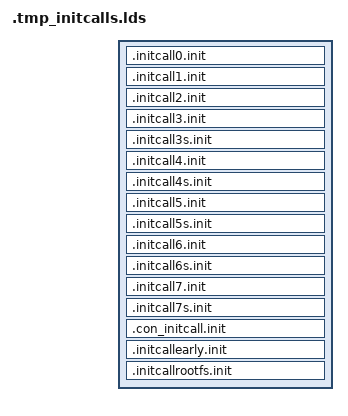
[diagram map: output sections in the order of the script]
SECTIONS {
	.initcall0.init : {
		*(.initcall0.init..kmod_core__515_845_bpf_jit_charge_init) ;
		*(.initcall0.init..kmod_min_addr__337_53_init_mmap_min_addr) ;
		*(.initcall0.init..kmod_pci__487_6842_pci_realloc_setup_params) ;
		*(.initcall0.init..kmod_inet_fragment__734_216_inet_frag_wq_init) ;
	}
	.initcall1.init : {
		*(.initcall1.init..kmod_fpsimd__355_1464_fpsimd_init) ;
		*(.initcall1.init..kmod_process__402_717_tagged_addr_init) ;
		*(.initcall1.init..kmod_topology__283_264_init_amu_fie) ;
		*(.initcall1.init..kmod_efi__363_173_arm64_efi_rt_init) ;
		*(.initcall1.init..kmod_armv8_deprecated__383_638_armv8_deprecated_init) ;
		*(.initcall1.init..kmod_kaslr__360_206_kaslr_init) ;
		*(.initcall1.init..kmod_cpu__492_1657_alloc_frozen_cpus) ;
		*(.initcall1.init..kmod_cpu__494_1704_cpu_hotplug_pm_sync_init) ;
		*(.initcall1.init..kmod_workqueue__573_5784_wq_sysfs_init) ;
		*(.initcall1.init..kmod_ksysfs__345_274_ksysfs_init) ;
		*(.initcall1.init..kmod_cpufreq_schedutil__558_853_schedutil_gov_init) ;
		*(.initcall1.init..kmod_main__462_962_pm_init) ;
		*(.initcall1.init..kmod_hibernate__470_1271_pm_disk_init) ;
		*(.initcall1.init..kmod_swap__466_1624_swsusp_header_init) ;
		*(.initcall1.init..kmod_update__452_350_rcu_set_runtime_mode) ;
		*(.initcall1.init..kmod_jiffies__324_69_init_jiffies_clocksource) ;
		*(.initcall1.init..kmod_core__442_4303_futex_init) ;
		*(.initcall1.init..kmod_cgroup__807_6030_cgroup_wq_init) ;
		*(.initcall1.init..kmod_cgroup_v1__385_1275_cgroup1_wq_init) ;
		*(.initcall1.init..kmod_trace_eprobe__407_1005_trace_events_eprobe_init_early) ;
		*(.initcall1.init..kmod_trace_events_synth__394_2307_trace_events_synth_init_early) ;
		*(.initcall1.init..kmod_trace_kprobe__419_1954_init_kprobe_trace_early) ;
		*(.initcall1.init..kmod_cpu_pm__293_213_cpu_pm_init) ;
		*(.initcall1.init..kmod_memcontrol__848_7607_mem_cgroup_swap_init) ;
		*(.initcall1.init..kmod_cma__403_177_cma_init_reserved_areas) ;
		*(.initcall1.init..kmod_fsnotify__368_572_fsnotify_init) ;
		*(.initcall1.init..kmod_locks__472_2983_filelock_init) ;
		*(.initcall1.init..kmod_binfmt_misc__399_834_init_misc_binfmt) ;
		*(.initcall1.init..kmod_binfmt_script__291_156_init_script_binfmt) ;
		*(.initcall1.init..kmod_binfmt_elf__404_2318_init_elf_binfmt) ;
		*(.initcall1.init..kmod_compat_binfmt_elf__404_2318_init_compat_elf_binfmt) ;
		*(.initcall1.init..kmod_configfs__379_178_configfs_init) ;
		*(.initcall1.init..kmod_debugfs__383_886_debugfs_init) ;
		*(.initcall1.init..kmod_tracefs__354_647_tracefs_init) ;
		*(.initcall1.init..kmod_inode__371_350_securityfs_init) ;
		*(.initcall1.init..kmod_gaf_v6__351_205_proca_init_gaf) ;
		*(.initcall1.init..kmod_random32__252_489_prandom_init_early) ;
		*(.initcall1.init..kmod_core__425_2329_pinctrl_init) ;
		*(.initcall1.init..kmod_gpiolib__449_4383_gpiolib_dev_init) ;
		*(.initcall1.init..kmod_crg_hi3516cv300__334_309_hi3516cv300_crg_init) ;
		*(.initcall1.init..kmod_clk_hi3519__334_194_hi3519_clk_init) ;
		*(.initcall1.init..kmod_clk_hi3559a__338_834_hi3559av100_crg_init) ;
		*(.initcall1.init..kmod_clk_hi3660__295_637_hi3660_clk_init) ;
		*(.initcall1.init..kmod_clk_hi3670__295_1016_hi3670_clk_init) ;
		*(.initcall1.init..kmod_crg_hi3798cv200__334_392_hi3798cv200_crg_init) ;
		*(.initcall1.init..kmod_clk_exynos5433__298_5728_exynos5433_cmu_init) ;
		*(.initcall1.init..kmod_virtio__361_534_virtio_init) ;
		*(.initcall1.init..kmod_core__562_6203_regulator_init) ;
		*(.initcall1.init..kmod_iommu__434_2807_iommu_init) ;
		*(.initcall1.init..kmod_component__300_123_component_debug_init) ;
		*(.initcall1.init..kmod_domain__518_2989_genpd_bus_init) ;
		*(.initcall1.init..kmod_soc__270_192_soc_bus_register) ;
		*(.initcall1.init..kmod_arch_topology__398_390_register_cpufreq_notifier) ;
		*(.initcall1.init..kmod_debugfs__302_256_opp_debug_init) ;
		*(.initcall1.init..kmod_cpufreq__535_2952_cpufreq_core_init) ;
		*(.initcall1.init..kmod_cpufreq_performance__319_44_cpufreq_gov_performance_init) ;
		*(.initcall1.init..kmod_cpufreq_powersave__319_38_cpufreq_gov_powersave_init) ;
		*(.initcall1.init..kmod_cpufreq_conservative__358_340_CPU_FREQ_GOV_CONSERVATIVE_init) ;
		*(.initcall1.init..kmod_cpuidle__477_792_cpuidle_init) ;
		*(.initcall1.init..kmod_arm_runtime__365_178_arm_dmi_init) ;
		*(.initcall1.init..kmod_hi3660_mailbox__339_291_hi3660_mbox_init) ;
		*(.initcall1.init..kmod_hi6220_mailbox__350_366_hi6220_mbox_init) ;
		*(.initcall1.init..kmod_socket__774_3158_sock_init) ;
		*(.initcall1.init..kmod_sock__884_3802_net_inuse_init) ;
		*(.initcall1.init..kmod_net_namespace__676_380_net_defaults_init) ;
		*(.initcall1.init..kmod_flow_dissector__791_1836_init_default_flow_dissectors) ;
		*(.initcall1.init..kmod_af_netlink__787_2914_netlink_proto_init) ;
		*(.initcall1.init..kmod_genetlink__670_1439_genl_init) ;
	}
	.initcall2.init : {
		*(.initcall2.init..kmod_debug_monitors__367_139_debug_monitors_init) ;
		*(.initcall2.init..kmod_irqdesc__310_335_irq_sysfs_init) ;
		*(.initcall2.init..kmod_pool__356_222_dma_atomic_pool_init) ;
		*(.initcall2.init..kmod_audit__692_1731_audit_init) ;
		*(.initcall2.init..kmod_tracepoint__307_140_release_early_probes) ;
		*(.initcall2.init..kmod_backing_dev__439_230_bdi_class_init) ;
		*(.initcall2.init..kmod_mm_init__389_206_mm_sysfs_init) ;
		*(.initcall2.init..kmod_page_alloc__663_8950_init_per_zone_wmark_min) ;
		*(.initcall2.init..kmod_ramoops__356_978_ramoops_init) ;
		*(.initcall2.init..kmod_mpi__345_64_mpi_init) ;
		*(.initcall2.init..kmod_kobject_uevent__661_814_kobject_uevent_init) ;
		*(.initcall2.init..kmod_probe__362_109_pcibus_class_init) ;
		*(.initcall2.init..kmod_pci_driver__508_1674_pci_driver_init) ;
		*(.initcall2.init..kmod_backlight__476_764_backlight_class_init) ;
		*(.initcall2.init..kmod_bus__471_331_amba_init) ;
		*(.initcall2.init..kmod_hi6220_reset__340_221_hi6220_reset_init) ;
		*(.initcall2.init..kmod_tty_io__408_3551_tty_class_init) ;
		*(.initcall2.init..kmod_serdev__323_859_serdev_init) ;
		*(.initcall2.init..kmod_iommu_sysfs__344_47_iommu_dev_init) ;
		*(.initcall2.init..kmod_drm_mipi_dsi__496_1343_mipi_dsi_bus_init) ;
		*(.initcall2.init..kmod_core__514_629_devlink_class_init) ;
		*(.initcall2.init..kmod_swnode__300_1176_software_node_init) ;
		*(.initcall2.init..kmod_wakeup__523_1266_wakeup_sources_debugfs_init) ;
		*(.initcall2.init..kmod_wakeup_stats__266_217_wakeup_sources_sysfs_init) ;
		*(.initcall2.init..kmod_regmap__442_3345_regmap_initcall) ;
		*(.initcall2.init..kmod_sram__303_474_sram_init) ;
		*(.initcall2.init..kmod_syscon__306_338_syscon_init) ;
		*(.initcall2.init..kmod_spi__585_4364_spi_init) ;
		*(.initcall2.init..kmod_spmi__402_600_spmi_init) ;
		*(.initcall2.init..kmod_i2c_core__522_1992_i2c_init) ;
		*(.initcall2.init..kmod_thermal_sys__534_1512_thermal_init) ;
		*(.initcall2.init..kmod_menu__286_579_init_menu) ;
		*(.initcall2.init..kmod_teo__284_534_teo_governor_init) ;
		*(.initcall2.init..kmod_rpmsg_core__339_749_rpmsg_init) ;
		*(.initcall2.init..kmod_rpmsg_char__413_555_rpmsg_chrdev_init) ;
	}
	.initcall3.init : {
		*(.initcall3.init..kmod_setup__373_287_reserve_memblock_reserved_regions) ;
		*(.initcall3.init..kmod_vdso__365_365_aarch32_alloc_vdso_pages) ;
		*(.initcall3.init..kmod_vdso__367_463_vdso_init) ;
		*(.initcall3.init..kmod_hw_breakpoint__379_1018_arch_hw_breakpoint_init) ;
		*(.initcall3.init..kmod_mmap__336_57_adjust_protection_map) ;
		*(.initcall3.init..kmod_context__369_394_asids_update_limit) ;
		*(.initcall3.init..kmod_kcmp__383_239_kcmp_cookies_init) ;
		*(.initcall3.init..kmod_cryptomgr__482_257_cryptomgr_init) ;
		*(.initcall3.init..kmod_clk_pll__287_76_samsung_pll_disable_early_timeout) ;
		*(.initcall3.init..kmod_dmaengine__363_293_dma_channel_table_init) ;
		*(.initcall3.init..kmod_dmaengine__424_1663_dma_bus_init) ;
		*(.initcall3.init..kmod_sunxi_mbus__345_127_sunxi_mbus_init) ;
		*(.initcall3.init..kmod_reset_hi3660__335_123_hi3660_reset_init) ;
		*(.initcall3.init..kmod_amba_pl011__497_3018_pl011_init) ;
		*(.initcall3.init..kmod_dma_iommu__392_1483_iommu_dma_init) ;
	}
	.initcall3s.init : {
		*(.initcall3s.init..kmod_platform__457_546_of_platform_default_populate_init) ;
	}
	.initcall4.init : {
		*(.initcall4.init..kmod_setup__375_415_topology_init) ;
		*(.initcall4.init..kmod_mte__453_601_register_mte_tcf_preferred_sysctl) ;
		*(.initcall4.init..kmod_user__308_263_uid_cache_init) ;
		*(.initcall4.init..kmod_params__392_974_param_sysfs_init) ;
		*(.initcall4.init..kmod_ucount__285_374_user_namespace_sysctl_init) ;
		*(.initcall4.init..kmod_stats__548_128_proc_schedstat_init) ;
		*(.initcall4.init..kmod_poweroff__187_45_pm_sysrq_init) ;
		*(.initcall4.init..kmod_profile__391_573_create_proc_profile) ;
		*(.initcall4.init..kmod_cgroup__815_6892_cgroup_sysfs_init) ;
		*(.initcall4.init..kmod_hung_task__460_322_hung_task_init) ;
		*(.initcall4.init..kmod_bpf_trace__720_2016_send_signal_irq_work_init) ;
		*(.initcall4.init..kmod_devmap__580_1145_dev_map_init) ;
		*(.initcall4.init..kmod_cpumap__556_824_cpu_map_init) ;
		*(.initcall4.init..kmod_net_namespace__523_566_netns_bpf_init) ;
		*(.initcall4.init..kmod_stackmap__512_738_stack_map_init) ;
		*(.initcall4.init..kmod_sysfs_btf__291_45_btf_vmlinux_init) ;
		*(.initcall4.init..kmod_oom_kill__493_728_oom_init) ;
		*(.initcall4.init..kmod_backing_dev__441_240_default_bdi_init) ;
		*(.initcall4.init..kmod_backing_dev__477_765_cgwb_init) ;
		*(.initcall4.init..kmod_percpu__518_3379_percpu_enable_async) ;
		*(.initcall4.init..kmod_compaction__559_3137_kcompactd_init) ;
		*(.initcall4.init..kmod_mmap__542_3764_init_user_reserve) ;
		*(.initcall4.init..kmod_mmap__546_3785_init_admin_reserve) ;
		*(.initcall4.init..kmod_mmap__548_3855_init_reserve_notifier) ;
		*(.initcall4.init..kmod_swap_state__473_911_swap_init_sysfs) ;
		*(.initcall4.init..kmod_swapfile__549_3858_swapfile_init) ;
		*(.initcall4.init..kmod_huge_memory__485_461_hugepage_init) ;
		*(.initcall4.init..kmod_memcontrol__839_7251_mem_cgroup_init) ;
		*(.initcall4.init..kmod_seqiv__384_183_seqiv_module_init) ;
		*(.initcall4.init..kmod_echainiv__384_160_echainiv_module_init) ;
		*(.initcall4.init..kmod_rsa_generic__352_281_rsa_init) ;
		*(.initcall4.init..kmod_cmac__303_311_crypto_cmac_module_init) ;
		*(.initcall4.init..kmod_hmac__380_254_hmac_module_init) ;
		*(.initcall4.init..kmod_xcbc__303_270_crypto_xcbc_module_init) ;
		*(.initcall4.init..kmod_crypto_null__369_221_crypto_null_mod_init) ;
		*(.initcall4.init..kmod_md5__303_245_md5_mod_init) ;
		*(.initcall4.init..kmod_sha1_generic__357_89_sha1_generic_mod_init) ;
		*(.initcall4.init..kmod_sha256_generic__355_113_sha256_generic_mod_init) ;
		*(.initcall4.init..kmod_sha512_generic__355_218_sha512_generic_mod_init) ;
		*(.initcall4.init..kmod_blake2b_generic__303_174_blake2b_mod_init) ;
		*(.initcall4.init..kmod_ecb__301_99_crypto_ecb_module_init) ;
		*(.initcall4.init..kmod_cbc__301_218_crypto_cbc_module_init) ;
		*(.initcall4.init..kmod_cts__378_405_crypto_cts_module_init) ;
		*(.initcall4.init..kmod_xts__378_469_xts_module_init) ;
		*(.initcall4.init..kmod_ctr__303_355_crypto_ctr_module_init) ;
		*(.initcall4.init..kmod_adiantum__395_613_adiantum_module_init) ;
		*(.initcall4.init..kmod_nhpoly1305__312_248_nhpoly1305_mod_init) ;
		*(.initcall4.init..kmod_gcm__396_1159_crypto_gcm_module_init) ;
		*(.initcall4.init..kmod_ccm__398_949_crypto_ccm_module_init) ;
		*(.initcall4.init..kmod_chacha20poly1305__396_671_chacha20poly1305_module_init) ;
		*(.initcall4.init..kmod_des_generic__299_125_des_generic_mod_init) ;
		*(.initcall4.init..kmod_twofish_generic__293_190_twofish_mod_init) ;
		*(.initcall4.init..kmod_aes_generic__293_1314_aes_init) ;
		*(.initcall4.init..kmod_chacha_generic__301_128_chacha_generic_mod_init) ;
		*(.initcall4.init..kmod_poly1305_generic__305_142_poly1305_mod_init) ;
		*(.initcall4.init..kmod_deflate__353_334_deflate_mod_init) ;
		*(.initcall4.init..kmod_crc32c_generic__303_161_crc32c_mod_init) ;
		*(.initcall4.init..kmod_crc32_generic__303_125_crc32_mod_init) ;
		*(.initcall4.init..kmod_authenc__500_464_crypto_authenc_module_init) ;
		*(.initcall4.init..kmod_authencesn__499_479_crypto_authenc_esn_module_init) ;
		*(.initcall4.init..kmod_lzo__347_158_lzo_mod_init) ;
		*(.initcall4.init..kmod_lzo_rle__347_158_lzorle_mod_init) ;
		*(.initcall4.init..kmod_lz4__324_155_lz4_mod_init) ;
		*(.initcall4.init..kmod_ansi_cprng__302_470_prng_mod_init) ;
		*(.initcall4.init..kmod_drbg__374_2144_drbg_init) ;
		*(.initcall4.init..kmod_ghash_generic__306_178_ghash_mod_init) ;
		*(.initcall4.init..kmod_zstd__353_253_zstd_mod_init) ;
		*(.initcall4.init..kmod_essiv__395_646_essiv_module_init) ;
		*(.initcall4.init..kmod_ecdh_generic__351_238_ecdh_init) ;
		*(.initcall4.init..kmod_bio__490_1747_init_bio) ;
		*(.initcall4.init..kmod_blk_ioc__423_423_blk_ioc_init) ;
		*(.initcall4.init..kmod_blk_mq__540_4089_blk_mq_init) ;
		*(.initcall4.init..kmod_genhd__444_887_genhd_device_init) ;
		*(.initcall4.init..kmod_blk_cgroup__517_1956_blkcg_init) ;
		*(.initcall4.init..kmod_blk_crypto__408_80_bio_crypt_ctx_init) ;
		*(.initcall4.init..kmod_io_wq__498_1414_io_wq_init) ;
		*(.initcall4.init..kmod_gpiolib__454_4510_gpiolib_debugfs_init) ;
		*(.initcall4.init..kmod_core__408_1244_pwm_debugfs_init) ;
		*(.initcall4.init..kmod_sysfs__266_546_pwm_sysfs_init) ;
		*(.initcall4.init..kmod_slot__370_380_pci_slot_init) ;
		*(.initcall4.init..kmod_clk_hi6220_stub__300_272_hi6220_stub_clk_init) ;
		*(.initcall4.init..kmod_clk_hi3660_stub__336_178_hi3660_stub_clk_init) ;
		*(.initcall4.init..kmod_fixed__452_348_regulator_fixed_voltage_init) ;
		*(.initcall4.init..kmod_misc__321_291_misc_init) ;
		*(.initcall4.init..kmod_iommu__358_155_iommu_subsys_init) ;
		*(.initcall4.init..kmod_arch_topology__393_209_register_cpu_capacity_sysctl) ;
		*(.initcall4.init..kmod_act8945a__454_82_act8945a_i2c_init) ;
		*(.initcall4.init..kmod_libnvdimm__463_606_libnvdimm_init) ;
		*(.initcall4.init..kmod_dax__417_719_dax_core_init) ;
		*(.initcall4.init..kmod_dma_buf__389_1604_dma_buf_init) ;
		*(.initcall4.init..kmod_dma_heap__403_483_dma_heap_init) ;
		*(.initcall4.init..kmod_scsi_mod__470_821_init_scsi) ;
		*(.initcall4.init..kmod_libphy__536_3260_phy_init) ;
		*(.initcall4.init..kmod_usb_common__469_432_usb_common_init) ;
		*(.initcall4.init..kmod_usbcore__491_1195_usb_init) ;
		*(.initcall4.init..kmod_udc_core__422_1789_usb_udc_init) ;
		*(.initcall4.init..kmod_typec__393_2181_typec_init) ;
		*(.initcall4.init..kmod_roles__320_399_usb_roles_init) ;
		*(.initcall4.init..kmod_serio__395_1051_serio_init) ;
		*(.initcall4.init..kmod_input_core__432_2653_input_init) ;
		*(.initcall4.init..kmod_rtc_core__344_478_rtc_init) ;
		*(.initcall4.init..kmod_i3c__512_2704_i3c_init) ;
		*(.initcall4.init..kmod_mc__352_323_media_devnode_init) ;
		*(.initcall4.init..kmod_videodev__500_1132_videodev_init) ;
		*(.initcall4.init..kmod_rc_core__373_2090_rc_core_init) ;
		*(.initcall4.init..kmod_cec__363_451_cec_devnode_init) ;
		*(.initcall4.init..kmod_pps_core__307_484_pps_init) ;
		*(.initcall4.init..kmod_ptp__439_465_ptp_init) ;
		*(.initcall4.init..kmod_power_supply__329_1398_power_supply_class_init) ;
		*(.initcall4.init..kmod_edac_core__357_163_edac_init) ;
		*(.initcall4.init..kmod_cpuidle_psci_domain__272_317_psci_idle_init_domains) ;
		*(.initcall4.init..kmod_mmc_core__493_2373_mmc_init) ;
		*(.initcall4.init..kmod_led_class__309_549_leds_init) ;
		*(.initcall4.init..kmod_scmi_module__520_2108_scmi_driver_init) ;
		*(.initcall4.init..kmod_efi__355_439_efisubsys_init) ;
		*(.initcall4.init..kmod_remoteproc__428_2864_remoteproc_init) ;
		*(.initcall4.init..kmod_devfreq__446_2024_devfreq_init) ;
		*(.initcall4.init..kmod_devfreq_event__277_482_devfreq_event_init) ;
		*(.initcall4.init..kmod_governor_simpleondemand__302_130_devfreq_simple_ondemand_init) ;
		*(.initcall4.init..kmod_governor_performance__302_48_devfreq_performance_init) ;
		*(.initcall4.init..kmod_governor_powersave__302_48_devfreq_powersave_init) ;
		*(.initcall4.init..kmod_governor_userspace__306_143_devfreq_userspace_init) ;
		*(.initcall4.init..kmod_governor_passive__303_177_devfreq_passive_init) ;
		*(.initcall4.init..kmod_industrialio__359_2139_iio_init) ;
		*(.initcall4.init..kmod_arm_pmu__391_975_arm_pmu_hp_init) ;
		*(.initcall4.init..kmod_ras__396_38_ras_init) ;
		*(.initcall4.init..kmod_nvmem_core__343_1922_nvmem_init) ;
		*(.initcall4.init..kmod_soundcore__308_65_init_soundcore) ;
		*(.initcall4.init..kmod_snd__320_426_alsa_sound_init) ;
		*(.initcall4.init..kmod_sock__890_4114_proto_init) ;
		*(.initcall4.init..kmod_dev__1210_11737_net_dev_init) ;
		*(.initcall4.init..kmod_neighbour__786_3766_neigh_init) ;
		*(.initcall4.init..kmod_fib_notifier__484_199_fib_notifier_init) ;
		*(.initcall4.init..kmod_fib_rules__783_1298_fib_rules_init) ;
		*(.initcall4.init..kmod_netprio_cgroup__680_295_init_cgroup_netprio) ;
		*(.initcall4.init..kmod_devlink__855_11573_devlink_init) ;
		*(.initcall4.init..kmod_sch_api__698_2354_pktsched_init) ;
		*(.initcall4.init..kmod_cls_api__840_3924_tc_filter_init) ;
		*(.initcall4.init..kmod_act_api__681_1719_tc_action_init) ;
		*(.initcall4.init..kmod_ethtool_nl__660_1036_ethnl_init) ;
		*(.initcall4.init..kmod_nexthop__822_3772_nexthop_init) ;
		*(.initcall4.init..kmod_bluetooth__683_804_bt_init) ;
		*(.initcall4.init..kmod_wext_core__484_408_wireless_nlevent_init) ;
		*(.initcall4.init..kmod_rfkill__366_1418_rfkill_init) ;
		*(.initcall4.init..kmod_ieee802154__483_374_wpan_phy_class_init) ;
		*(.initcall4.init..kmod_mac802154__694_235_ieee802154_init) ;
		*(.initcall4.init..kmod_nfc__670_1239_nfc_init) ;
	}
	.initcall4s.init : {
		*(.initcall4s.init..kmod_cpufeature__397_2979_init_32bit_el0_mask) ;
		*(.initcall4s.init..kmod_watchdog__462_475_watchdog_init) ;
	}
	.initcall5.init : {
		*(.initcall5.init..kmod_debug_monitors__365_63_create_debug_debugfs_entry) ;
		*(.initcall5.init..kmod_resource__366_1876_iomem_init_inode) ;
		*(.initcall5.init..kmod_energy_model__301_99_em_debug_init) ;
		*(.initcall5.init..kmod_clocksource__347_1074_clocksource_done_booting) ;
		*(.initcall5.init..kmod_trace__487_9856_tracer_init_tracefs) ;
		*(.initcall5.init..kmod_trace_printk__386_415_init_trace_printk_function_export) ;
		*(.initcall5.init..kmod_trace_events_synth__396_2331_trace_events_synth_init) ;
		*(.initcall5.init..kmod_bpf_trace__725_2069_bpf_event_init) ;
		*(.initcall5.init..kmod_trace_kprobe__421_1984_init_kprobe_trace) ;
		*(.initcall5.init..kmod_trace_dynevent__391_276_init_dynamic_event) ;
		*(.initcall5.init..kmod_trace_uprobe__429_1674_init_uprobe_trace) ;
		*(.initcall5.init..kmod_inode__539_839_bpf_init) ;
		*(.initcall5.init..kmod_btf__780_6178_btf_module_init) ;
		*(.initcall5.init..kmod_pipe__470_1450_init_pipe_fs) ;
		*(.initcall5.init..kmod_fs_writeback__541_1175_cgroup_writeback_init) ;
		*(.initcall5.init..kmod_inotify_user__486_875_inotify_user_setup) ;
		*(.initcall5.init..kmod_eventpoll__765_2452_eventpoll_init) ;
		*(.initcall5.init..kmod_anon_inodes__347_241_anon_inode_init) ;
		*(.initcall5.init..kmod_locks__470_2960_proc_locks_init) ;
		*(.initcall5.init..kmod_iomap__478_1539_iomap_init) ;
		*(.initcall5.init..kmod_dquot__487_3072_dquot_init) ;
		*(.initcall5.init..kmod_proc__283_19_proc_cmdline_init) ;
		*(.initcall5.init..kmod_proc__308_98_proc_consoles_init) ;
		*(.initcall5.init..kmod_proc__311_32_proc_cpuinfo_init) ;
		*(.initcall5.init..kmod_proc__405_60_proc_devices_init) ;
		*(.initcall5.init..kmod_proc__323_42_proc_interrupts_init) ;
		*(.initcall5.init..kmod_proc__338_33_proc_loadavg_init) ;
		*(.initcall5.init..kmod_proc__451_186_proc_meminfo_init) ;
		*(.initcall5.init..kmod_proc__326_242_proc_stat_init) ;
		*(.initcall5.init..kmod_proc__323_45_proc_uptime_init) ;
		*(.initcall5.init..kmod_proc__283_23_proc_version_init) ;
		*(.initcall5.init..kmod_proc__323_33_proc_softirqs_init) ;
		*(.initcall5.init..kmod_proc__315_66_proc_kmsg_init) ;
		*(.initcall5.init..kmod_proc__462_338_proc_page_init) ;
		*(.initcall5.init..kmod_proc__285_96_proc_boot_config_init) ;
		*(.initcall5.init..kmod_ramfs__427_295_init_ramfs_fs) ;
		*(.initcall5.init..kmod_dynamic_debug__718_1143_dynamic_debug_init_control) ;
		*(.initcall5.init..kmod_mem__471_777_chr_dev_init) ;
		*(.initcall5.init..kmod_firmware_class__468_1655_firmware_class_init) ;
		*(.initcall5.init..kmod_powercap_sys__333_677_powercap_init) ;
		*(.initcall5.init..kmod_sysctl_net_core__723_666_sysctl_core_init) ;
		*(.initcall5.init..kmod_eth__734_499_eth_offload_init) ;
		*(.initcall5.init..kmod_af_inet__829_1933_ipv4_offload_init) ;
		*(.initcall5.init..kmod_af_inet__832_2064_inet_init) ;
		*(.initcall5.init..kmod_unix__722_3465_af_unix_init) ;
		*(.initcall5.init..kmod_ip6_offload__757_448_ipv6_offload_init) ;
		*(.initcall5.init..kmod_vlan_core__508_566_vlan_offload_init) ;
		*(.initcall5.init..kmod_xsk__787_1520_xsk_init) ;
	}
	.initcall5s.init : {
		*(.initcall5s.init..kmod_quirks__460_194_pci_apply_final_quirks) ;
	}
	.initcall6.init : {
		*(.initcall6.init..kmod_setup__377_449_register_arm64_panic_block) ;
		*(.initcall6.init..kmod_cpuinfo__302_328_cpuinfo_regs_init) ;
		*(.initcall6.init..kmod_cpufeature__394_1370_aarch32_el0_sysfs_init) ;
		*(.initcall6.init..kmod_perf_event__415_1319_armv8_pmu_driver_init) ;
		*(.initcall6.init..kmod_uprobes__370_208_arch_init_uprobes) ;
		*(.initcall6.init..kmod_kvm__609_2373_arm_init) ;
		*(.initcall6.init..kmod_sha1_ce__310_146_cpu_feature_match_SHA1_init) ;
		*(.initcall6.init..kmod_sha2_ce__312_182_cpu_feature_match_SHA2_init) ;
		*(.initcall6.init..kmod_sha512_ce__311_120_cpu_feature_match_SHA512_init) ;
		*(.initcall6.init..kmod_ghash_ce__404_623_ghash_ce_mod_init) ;
		*(.initcall6.init..kmod_aes_ce_cipher__298_178_cpu_feature_match_AES_init) ;
		*(.initcall6.init..kmod_aes_glue_ce__414_1050_cpu_feature_match_AES_init) ;
		*(.initcall6.init..kmod_sha256_arm64__312_194_sha256_mod_init) ;
		*(.initcall6.init..kmod_sha512_arm64__312_91_sha512_mod_init) ;
		*(.initcall6.init..kmod_chacha_neon__305_232_chacha_simd_mod_init) ;
		*(.initcall6.init..kmod_poly1305_neon__309_226_neon_poly1305_mod_init) ;
		*(.initcall6.init..kmod_exec_domain__377_35_proc_execdomains_init) ;
		*(.initcall6.init..kmod_panic__383_754_register_warn_debugfs) ;
		*(.initcall6.init..kmod_cpu__501_2647_cpuhp_sysfs_init) ;
		*(.initcall6.init..kmod_resource__348_137_ioresources_init) ;
		*(.initcall6.init..kmod_psi__578_1462_psi_proc_init) ;
		*(.initcall6.init..kmod_user__455_462_snapshot_device_init) ;
		*(.initcall6.init..kmod_generic_chip__314_665_irq_gc_init_ops) ;
		*(.initcall6.init..kmod_pm__451_249_irq_pm_init_ops) ;
		*(.initcall6.init..kmod_timekeeping__370_1905_timekeeping_init_ops) ;
		*(.initcall6.init..kmod_clocksource__360_1475_init_clocksource_sysfs) ;
		*(.initcall6.init..kmod_timer_list__345_359_init_timer_list_procfs) ;
		*(.initcall6.init..kmod_alarmtimer__406_964_alarmtimer_init) ;
		*(.initcall6.init..kmod_posix_timers__381_280_init_posix_timers) ;
		*(.initcall6.init..kmod_clockevents__354_776_clockevents_init_sysfs) ;
		*(.initcall6.init..kmod_sched_clock__297_300_sched_clock_syscore_init) ;
		*(.initcall6.init..kmod_module__460_4821_proc_modules_init) ;
		*(.initcall6.init..kmod_kallsyms__505_864_kallsyms_init) ;
		*(.initcall6.init..kmod_configs__291_75_ikconfig_init) ;
		*(.initcall6.init..kmod_kheaders__291_61_ikheaders_init) ;
		*(.initcall6.init..kmod_audit_watch__436_503_audit_watch_init) ;
		*(.initcall6.init..kmod_audit_fsnotify__420_193_audit_fsnotify_init) ;
		*(.initcall6.init..kmod_audit_tree__449_1085_audit_tree_init) ;
		*(.initcall6.init..kmod_seccomp__592_2369_seccomp_sysctl_init) ;
		*(.initcall6.init..kmod_utsname_sysctl__236_144_utsname_sysctl_init) ;
		*(.initcall6.init..kmod_tracepoint__331_740_init_tracepoints) ;
		*(.initcall6.init..kmod_core__827_13590_perf_event_sysfs_init) ;
		*(.initcall6.init..kmod_system_keyring__248_135_system_trusted_keyring_init) ;
		*(.initcall6.init..kmod_vmscan__703_7542_kswapd_init) ;
		*(.initcall6.init..kmod_vmstat__482_2249_extfrag_debug_init) ;
		*(.initcall6.init..kmod_mm_init__387_194_mm_compute_batch_init) ;
		*(.initcall6.init..kmod_slab_common__504_1207_slab_proc_init) ;
		*(.initcall6.init..kmod_workingset__489_736_workingset_init) ;
		*(.initcall6.init..kmod_vmalloc__497_4078_proc_vmalloc_init) ;
		*(.initcall6.init..kmod_memblock__412_2592_memblock_memsize_init) ;
		*(.initcall6.init..kmod_memblock__414_2610_memblock_init_debugfs) ;
		*(.initcall6.init..kmod_sec_mm__291_26_sec_mm_init) ;
		*(.initcall6.init..kmod_swapfile__507_2831_procswaps_init) ;
		*(.initcall6.init..kmod_slub__533_6250_slab_sysfs_init) ;
		*(.initcall6.init..kmod_slub__541_6431_slab_debugfs_init) ;
		*(.initcall6.init..kmod_cleancache__346_349_init_cleancache) ;
		*(.initcall6.init..kmod_reclaim__325_425_damon_reclaim_init) ;
		*(.initcall6.init..kmod_io_record__452_487_io_record_init) ;
		*(.initcall6.init..kmod_fcntl__401_1103_fcntl_init) ;
		*(.initcall6.init..kmod_filesystems__379_258_proc_filesystems_init) ;
		*(.initcall6.init..kmod_fs_writeback__565_2392_start_dirtytime_writeback) ;
		*(.initcall6.init..kmod_direct_io__410_1379_dio_init) ;
		*(.initcall6.init..kmod_dlog_hook__296_183_dlog_keyword_hash_init) ;
		*(.initcall6.init..kmod_userfaultfd__530_2176_userfaultfd_init) ;
		*(.initcall6.init..kmod_aio__433_280_aio_setup) ;
		*(.initcall6.init..kmod_mbcache__304_477_mbcache_init) ;
		*(.initcall6.init..kmod_quota_v2__297_436_init_v2_quota_format) ;
		*(.initcall6.init..kmod_proc__377_231_fslog_init) ;
		*(.initcall6.init..kmod_devpts__364_637_init_devpts_fs) ;
		*(.initcall6.init..kmod_ext4__836_6758_ext4_init_fs) ;
		*(.initcall6.init..kmod_jbd2__493_3203_journal_init) ;
		*(.initcall6.init..kmod_fat__440_2020_init_fat_fs) ;
		*(.initcall6.init..kmod_vfat__379_1085_init_vfat_fs) ;
		*(.initcall6.init..kmod_msdos__377_689_init_msdos_fs) ;
		*(.initcall6.init..kmod_sdfat_fs__465_5569_init_sdfat_fs) ;
		*(.initcall6.init..kmod_exfat__408_834_init_exfat_fs) ;
		*(.initcall6.init..kmod_nls_cp437__291_384_init_nls_cp437) ;
		*(.initcall6.init..kmod_nls_cp737__291_347_init_nls_cp737) ;
		*(.initcall6.init..kmod_nls_cp775__291_316_init_nls_cp775) ;
		*(.initcall6.init..kmod_nls_cp850__291_312_init_nls_cp850) ;
		*(.initcall6.init..kmod_nls_cp852__291_334_init_nls_cp852) ;
		*(.initcall6.init..kmod_nls_cp855__291_296_init_nls_cp855) ;
		*(.initcall6.init..kmod_nls_cp857__291_298_init_nls_cp857) ;
		*(.initcall6.init..kmod_nls_cp860__291_361_init_nls_cp860) ;
		*(.initcall6.init..kmod_nls_cp861__291_384_init_nls_cp861) ;
		*(.initcall6.init..kmod_nls_cp862__291_418_init_nls_cp862) ;
		*(.initcall6.init..kmod_nls_cp863__291_378_init_nls_cp863) ;
		*(.initcall6.init..kmod_nls_cp864__291_404_init_nls_cp864) ;
		*(.initcall6.init..kmod_nls_cp865__291_384_init_nls_cp865) ;
		*(.initcall6.init..kmod_nls_cp866__291_302_init_nls_cp866) ;
		*(.initcall6.init..kmod_nls_cp869__291_312_init_nls_cp869) ;
		*(.initcall6.init..kmod_nls_cp874__291_271_init_nls_cp874) ;
		*(.initcall6.init..kmod_nls_cp932__291_7929_init_nls_cp932) ;
		*(.initcall6.init..kmod_nls_euc_jp__291_577_init_nls_euc_jp) ;
		*(.initcall6.init..kmod_nls_cp936__291_11107_init_nls_cp936) ;
		*(.initcall6.init..kmod_nls_cp949__291_13942_init_nls_cp949) ;
		*(.initcall6.init..kmod_nls_cp950__291_9478_init_nls_cp950) ;
		*(.initcall6.init..kmod_nls_cp1250__291_343_init_nls_cp1250) ;
		*(.initcall6.init..kmod_nls_cp1251__291_298_init_nls_cp1251) ;
		*(.initcall6.init..kmod_nls_ascii__291_163_init_nls_ascii) ;
		*(.initcall6.init..kmod_nls_iso8859_1__291_254_init_nls_iso8859_1) ;
		*(.initcall6.init..kmod_nls_iso8859_2__291_305_init_nls_iso8859_2) ;
		*(.initcall6.init..kmod_nls_iso8859_3__291_305_init_nls_iso8859_3) ;
		*(.initcall6.init..kmod_nls_iso8859_4__291_305_init_nls_iso8859_4) ;
		*(.initcall6.init..kmod_nls_iso8859_5__291_269_init_nls_iso8859_5) ;
		*(.initcall6.init..kmod_nls_iso8859_6__291_260_init_nls_iso8859_6) ;
		*(.initcall6.init..kmod_nls_iso8859_7__291_314_init_nls_iso8859_7) ;
		*(.initcall6.init..kmod_nls_cp1255__291_380_init_nls_cp1255) ;
		*(.initcall6.init..kmod_nls_iso8859_9__291_269_init_nls_iso8859_9) ;
		*(.initcall6.init..kmod_nls_iso8859_13__291_282_init_nls_iso8859_13) ;
		*(.initcall6.init..kmod_nls_iso8859_14__291_338_init_nls_iso8859_14) ;
		*(.initcall6.init..kmod_nls_iso8859_15__291_304_init_nls_iso8859_15) ;
		*(.initcall6.init..kmod_nls_koi8_r__291_320_init_nls_koi8_r) ;
		*(.initcall6.init..kmod_nls_koi8_u__291_327_init_nls_koi8_u) ;
		*(.initcall6.init..kmod_nls_koi8_ru__291_79_init_nls_koi8_ru) ;
		*(.initcall6.init..kmod_nls_utf8__291_65_init_nls_utf8) ;
		*(.initcall6.init..kmod_mac_celtic__291_598_init_nls_macceltic) ;
		*(.initcall6.init..kmod_mac_centeuro__291_528_init_nls_maccenteuro) ;
		*(.initcall6.init..kmod_mac_croatian__291_598_init_nls_maccroatian) ;
		*(.initcall6.init..kmod_mac_cyrillic__291_493_init_nls_maccyrillic) ;
		*(.initcall6.init..kmod_mac_gaelic__291_563_init_nls_macgaelic) ;
		*(.initcall6.init..kmod_mac_greek__291_493_init_nls_macgreek) ;
		*(.initcall6.init..kmod_mac_iceland__291_598_init_nls_maciceland) ;
		*(.initcall6.init..kmod_mac_inuit__291_528_init_nls_macinuit) ;
		*(.initcall6.init..kmod_mac_romanian__291_598_init_nls_macromanian) ;
		*(.initcall6.init..kmod_mac_roman__291_633_init_nls_macroman) ;
		*(.initcall6.init..kmod_mac_turkish__291_598_init_nls_macturkish) ;
		*(.initcall6.init..kmod_ksmbd__796_645_ksmbd_server_init) ;
		*(.initcall6.init..kmod_ntfs__440_3196_init_ntfs_fs) ;
		*(.initcall6.init..kmod_fuse__586_2271_fuse_init) ;
		*(.initcall6.init..kmod_virtiofs__586_1532_virtio_fs_init) ;
		*(.initcall6.init..kmod_overlay__383_2260_ovl_init) ;
		*(.initcall6.init..kmod_incrementalfs__348_43_init_incfs_module) ;
		*(.initcall6.init..kmod_f2fs__617_5002_init_f2fs_fs) ;
		*(.initcall6.init..kmod_erofs__522_963_erofs_module_init) ;
		*(.initcall6.init..kmod_proc__338_58_key_proc_init) ;
		*(.initcall6.init..kmod_selinux__820_7600_selinux_nf_ip_init) ;
		*(.initcall6.init..kmod_selinux__720_2250_init_sel_fs) ;
		*(.initcall6.init..kmod_selinux__429_121_selnl_init) ;
		*(.initcall6.init..kmod_selinux__725_279_sel_netif_init) ;
		*(.initcall6.init..kmod_selinux__728_304_sel_netnode_init) ;
		*(.initcall6.init..kmod_selinux__728_238_sel_netport_init) ;
		*(.initcall6.init..kmod_selinux__762_3828_aurule_init) ;
		*(.initcall6.init..kmod_defex_lsm__378_161_defex_lsm_init) ;
		*(.initcall6.init..kmod_dsms_init__291_69_dsms_init) ;
		*(.initcall6.init..kmod_jitterentropy_rng__296_217_jent_mod_init) ;
		*(.initcall6.init..kmod_asymmetric_keys__300_653_asymmetric_key_init) ;
		*(.initcall6.init..kmod_x509_key_parser__297_269_x509_key_init) ;
		*(.initcall6.init..kmod_fops__467_665_blkdev_init) ;
		*(.initcall6.init..kmod_genhd__463_1265_proc_genhd_init) ;
		*(.initcall6.init..kmod_bsg__428_268_bsg_init) ;
		*(.initcall6.init..kmod_blk_ioprio__431_241_ioprio_init) ;
		*(.initcall6.init..kmod_blk_iocost__580_3485_ioc_init) ;
		*(.initcall6.init..kmod_mq_deadline__425_1240_deadline_init) ;
		*(.initcall6.init..kmod_kyber_iosched__458_1049_kyber_init) ;
		*(.initcall6.init..kmod_bfq__540_7377_bfq_init) ;
		*(.initcall6.init..kmod_io_uring__1026_11111_io_uring_init) ;
		*(.initcall6.init..kmod_libblake2s__291_69_blake2s_mod_init) ;
		*(.initcall6.init..kmod_libchacha20poly1305__378_369_chacha20poly1305_init) ;
		*(.initcall6.init..kmod_libcurve25519__295_28_curve25519_init) ;
		*(.initcall6.init..kmod_libcrc32c__297_74_libcrc32c_mod_init) ;
		*(.initcall6.init..kmod_ts_kmp__295_152_init_kmp) ;
		*(.initcall6.init..kmod_ts_bm__297_204_init_bm) ;
		*(.initcall6.init..kmod_ts_fsm__295_336_init_fsm) ;
		*(.initcall6.init..kmod_percpu_counter__312_257_percpu_counter_startup) ;
		*(.initcall6.init..kmod_audit__342_85_audit_classes_init) ;
		*(.initcall6.init..kmod_digsig__350_276_digsig_init) ;
		*(.initcall6.init..kmod_sg_pool__347_191_sg_pool_init) ;
		*(.initcall6.init..kmod_irq_mbigen__341_388_mbigen_platform_driver_init) ;
		*(.initcall6.init..kmod_qcom_ebi2__336_403_qcom_ebi2_driver_init) ;
		*(.initcall6.init..kmod_simple_pm_bus__303_91_simple_pm_bus_driver_init) ;
		*(.initcall6.init..kmod_phy_core__480_1200_phy_core_init) ;
		*(.initcall6.init..kmod_phy_exynos_dp_video__451_115_exynos_dp_video_phy_driver_init) ;
		*(.initcall6.init..kmod_phy_exynos_mipi_video__453_365_exynos_mipi_video_phy_driver_init) ;
		*(.initcall6.init..kmod_phy_exynos5_usbdrd__452_945_exynos5_usb3drd_phy_init) ;
		*(.initcall6.init..kmod_pinctrl_single__345_1990_pcs_driver_init) ;
		*(.initcall6.init..kmod_pinctrl_sun50i_a100__302_708_a100_pinctrl_driver_init) ;
		*(.initcall6.init..kmod_pinctrl_sun50i_a100_r__302_105_a100_r_pinctrl_driver_init) ;
		*(.initcall6.init..kmod_pinctrl_sun50i_h616__302_548_h616_pinctrl_driver_init) ;
		*(.initcall6.init..kmod_pinctrl_sun50i_h616_r__298_56_sun50i_h616_r_pinctrl_driver_init) ;
		*(.initcall6.init..kmod_gpio_generic__340_816_bgpio_driver_init) ;
		*(.initcall6.init..kmod_gpio_pl061__451_424_pl061_gpio_driver_init) ;
		*(.initcall6.init..kmod_pcieportdrv__358_274_pcie_portdrv_init) ;
		*(.initcall6.init..kmod_proc__367_469_pci_proc_init) ;
		*(.initcall6.init..kmod_pci_epc_core__363_849_pci_epc_init) ;
		*(.initcall6.init..kmod_pci_epf_core__373_561_pci_epf_init) ;
		*(.initcall6.init..kmod_pci_host_generic__357_87_gen_pci_driver_init) ;
		*(.initcall6.init..kmod_pcie_designware_plat__358_192_dw_plat_pcie_driver_init) ;
		*(.initcall6.init..kmod_pcie_qcom__477_1580_qcom_pcie_driver_init) ;
		*(.initcall6.init..kmod_pcie_kirin__359_486_kirin_pcie_driver_init) ;
		*(.initcall6.init..kmod_clk_fixed_factor__313_293_of_fixed_factor_clk_driver_init) ;
		*(.initcall6.init..kmod_clk_fixed_rate__344_219_of_fixed_clk_driver_init) ;
		*(.initcall6.init..kmod_clk_gpio__273_249_gpio_clk_driver_init) ;
		*(.initcall6.init..kmod_clk_scpi__307_310_scpi_clocks_driver_init) ;
		*(.initcall6.init..kmod_clk_exynos_audss__337_303_exynos_audss_clk_driver_init) ;
		*(.initcall6.init..kmod_clk_exynos_clkout__336_240_exynos_clkout_driver_init) ;
		*(.initcall6.init..kmod_qcom_geni_se__370_919_geni_se_driver_init) ;
		*(.initcall6.init..kmod_sunxi_sram__335_411_sunxi_sram_driver_init) ;
		*(.initcall6.init..kmod_reset_scmi__305_128_scmi_reset_driver_init) ;
		*(.initcall6.init..kmod_reset_simple__296_204_reset_simple_driver_init) ;
		*(.initcall6.init..kmod_n_null__312_63_n_null_init) ;
		*(.initcall6.init..kmod_pty__367_947_pty_init) ;
		*(.initcall6.init..kmod_sysrq__475_1210_sysrq_init) ;
		*(.initcall6.init..kmod_hvc_dcc__348_123_hvc_dcc_init) ;
		*(.initcall6.init..kmod_8250__382_1242_serial8250_init) ;
		*(.initcall6.init..kmod_8250_pci__374_6477_serial_pci_driver_init) ;
		*(.initcall6.init..kmod_8250_dw__371_738_dw8250_platform_driver_init) ;
		*(.initcall6.init..kmod_8250_of__365_350_of_platform_serial_driver_init) ;
		*(.initcall6.init..kmod_samsung_tty__384_2950_samsung_serial_driver_init) ;
		*(.initcall6.init..kmod_qcom_geni_serial__375_1650_qcom_geni_serial_init) ;
		*(.initcall6.init..kmod_sprd_serial__386_1295_sprd_platform_driver_init) ;
		*(.initcall6.init..kmod_rng_core__322_650_hwrng_modinit) ;
		*(.initcall6.init..kmod_hisi_rng__339_117_hisi_rng_driver_init) ;
		*(.initcall6.init..kmod_arm_smccc_trng__310_119_smccc_trng_driver_init) ;
		*(.initcall6.init..kmod_drm_kms_helper__468_87_drm_kms_helper_init) ;
		*(.initcall6.init..kmod_drm__479_1078_drm_core_init) ;
		*(.initcall6.init..kmod_topology__350_154_topology_sysfs_init) ;
		*(.initcall6.init..kmod_cacheinfo__268_675_cacheinfo_sysfs_init) ;
		*(.initcall6.init..kmod_devcoredump__352_422_devcoredump_init) ;
		*(.initcall6.init..kmod_brd__460_536_brd_init) ;
		*(.initcall6.init..kmod_loop__496_2649_loop_init) ;
		*(.initcall6.init..kmod_nd_pmem__426_648_nd_pmem_driver_init) ;
		*(.initcall6.init..kmod_nd_btt__465_1735_nd_btt_init) ;
		*(.initcall6.init..kmod_of_pmem__387_112_of_pmem_region_driver_init) ;
		*(.initcall6.init..kmod_deferred_free_helper__452_137_deferred_freelist_init) ;
		*(.initcall6.init..kmod_page_pool__461_269_dmabuf_page_pool_init_shrinker) ;
		*(.initcall6.init..kmod_hpa_heap__392_889_hpa_dma_heap_init) ;
		*(.initcall6.init..kmod_ufshcd_core__601_10031_ufshcd_core_init) ;
		*(.initcall6.init..kmod_tc_dwc_g210_pltfrm__462_102_tc_dwc_g210_pltfm_driver_init) ;
		*(.initcall6.init..kmod_ufshcd_pci__470_616_ufshcd_pci_driver_init) ;
		*(.initcall6.init..kmod_ufs_hisi__463_595_ufs_hisi_pltform_init) ;
		*(.initcall6.init..kmod_sd_mod__496_3814_init_sd) ;
		*(.initcall6.init..kmod_dummy__478_209_dummy_init_module) ;
		*(.initcall6.init..kmod_wireguard__735_71_mod_init) ;
		*(.initcall6.init..kmod_ifb__500_355_ifb_init_module) ;
		*(.initcall6.init..kmod_macsec__714_4371_macsec_init) ;
		*(.initcall6.init..kmod_loopback__670_277_blackhole_netdev_init) ;
		*(.initcall6.init..kmod_ax88796b__413_122_phy_module_init) ;
		*(.initcall6.init..kmod_fixed_phy__484_369_fixed_mdio_bus_init) ;
		*(.initcall6.init..kmod_tun__873_3878_tun_init) ;
		*(.initcall6.init..kmod_veth__773_1824_veth_init) ;
		*(.initcall6.init..kmod_can_dev__674_528_can_dev_init) ;
		*(.initcall6.init..kmod_ppp_generic__715_3592_ppp_init) ;
		*(.initcall6.init..kmod_bsd_comp__322_1167_bsdcomp_init) ;
		*(.initcall6.init..kmod_ppp_deflate__322_631_deflate_init) ;
		*(.initcall6.init..kmod_ppp_mppe__355_687_ppp_mppe_init) ;
		*(.initcall6.init..kmod_pppox__662_152_pppox_init) ;
		*(.initcall6.init..kmod_pptp__745_693_pptp_init_module) ;
		*(.initcall6.init..kmod_rtl8150__482_953_rtl8150_driver_init) ;
		*(.initcall6.init..kmod_r8152__757_9935_rtl8152_driver_init) ;
		*(.initcall6.init..kmod_asix__489_1442_asix_driver_init) ;
		*(.initcall6.init..kmod_ax88179_178a__487_1900_ax88179_178a_driver_init) ;
		*(.initcall6.init..kmod_cdc_ether__485_1067_cdc_driver_init) ;
		*(.initcall6.init..kmod_cdc_eem__483_362_eem_driver_init) ;
		*(.initcall6.init..kmod_usbnet__522_2219_usbnet_init) ;
		*(.initcall6.init..kmod_cdc_ncm__549_2041_cdc_ncm_driver_init) ;
		*(.initcall6.init..kmod_aqc111__485_1491_aq_driver_init) ;
		*(.initcall6.init..kmod_r8153_ecm__478_166_r8153_ecm_driver_init) ;
		*(.initcall6.init..kmod_uio__361_1083_uio_init) ;
		*(.initcall6.init..kmod_dwc3__467_2133_dwc3_driver_init) ;
		*(.initcall6.init..kmod_dwc3_haps__361_148_dwc3_haps_driver_init) ;
		*(.initcall6.init..kmod_dwc3_of_simple__351_195_dwc3_of_simple_driver_init) ;
		*(.initcall6.init..kmod_dwc3_qcom__464_1037_dwc3_qcom_driver_init) ;
		*(.initcall6.init..kmod_ehci_hcd__536_1371_ehci_hcd_init) ;
		*(.initcall6.init..kmod_ehci_pci__367_432_ehci_pci_init) ;
		*(.initcall6.init..kmod_ehci_platform__470_535_ehci_platform_init) ;
		*(.initcall6.init..kmod_xhci_hcd__419_5699_xhci_hcd_init) ;
		*(.initcall6.init..kmod_xhci_pci__482_718_xhci_pci_init) ;
		*(.initcall6.init..kmod_xhci_plat_hcd__466_580_xhci_plat_init) ;
		*(.initcall6.init..kmod_cdc_acm__365_2088_acm_init) ;
		*(.initcall6.init..kmod_uas__427_1282_uas_init) ;
		*(.initcall6.init..kmod_usb_storage__435_1272_usb_storage_driver_init) ;
		*(.initcall6.init..kmod_libcomposite__419_1966_gadget_cfs_init) ;
		*(.initcall6.init..kmod_usb_f_acm__360_858_acmmod_init) ;
		*(.initcall6.init..kmod_usb_f_uts__360_826_utsmod_init) ;
		*(.initcall6.init..kmod_u_serial__375_1525_userial_init) ;
		*(.initcall6.init..kmod_usb_f_serial__357_396_gsermod_init) ;
		*(.initcall6.init..kmod_u_ether__507_1443_gether_init) ;
		*(.initcall6.init..kmod_usb_f_ncm__489_1757_ncmmod_init) ;
		*(.initcall6.init..kmod_usb_f_ecm__486_963_ecmmod_init) ;
		*(.initcall6.init..kmod_usb_f_eem__486_678_eemmod_init) ;
		*(.initcall6.init..kmod_usb_f_rndis__488_1060_rndismod_init) ;
		*(.initcall6.init..kmod_usb_f_mass_storage__450_3478_mass_storagemod_init) ;
		*(.initcall6.init..kmod_usb_f_fs__430_3898_ffsmod_init) ;
		*(.initcall6.init..kmod_usb_f_uac2__382_2005_uac2mod_init) ;
		*(.initcall6.init..kmod_usb_f_uvc__524_1049_uvcmod_init) ;
		*(.initcall6.init..kmod_usb_f_midi__366_1425_midimod_init) ;
		*(.initcall6.init..kmod_usb_f_hid__381_1319_hidmod_init) ;
		*(.initcall6.init..kmod_usb_f_accessory__387_1573_accessorymod_init) ;
		*(.initcall6.init..kmod_usb_f_audio_source__367_1070_audio_sourcemod_init) ;
		*(.initcall6.init..kmod_tcpci__459_916_tcpci_i2c_driver_init) ;
		*(.initcall6.init..kmod_serport__357_310_serport_init) ;
		*(.initcall6.init..kmod_input_leds__307_209_input_leds_init) ;
		*(.initcall6.init..kmod_evdev__401_1518_evdev_init) ;
		*(.initcall6.init..kmod_atkbd__361_1956_atkbd_init) ;
		*(.initcall6.init..kmod_xpad__359_2007_xpad_driver_init) ;
		*(.initcall6.init..kmod_uinput__309_1129_uinput_misc_init) ;
		*(.initcall6.init..kmod_rtc_pl030__450_170_pl030_driver_init) ;
		*(.initcall6.init..kmod_rtc_pl031__450_466_pl031_driver_init) ;
		*(.initcall6.init..kmod_i2c_dev__466_781_i2c_dev_init) ;
		*(.initcall6.init..kmod_ir_kbd_i2c__458_950_ir_kbd_driver_init) ;
		*(.initcall6.init..kmod_uvcvideo__544_2924_uvc_init) ;
		*(.initcall6.init..kmod_gspca_main__510_1714_gspca_init) ;
		*(.initcall6.init..kmod_ptp_kvm__405_153_ptp_kvm_init) ;
		*(.initcall6.init..kmod_hisi_reboot__334_80_hisi_reboot_driver_init) ;
		*(.initcall6.init..kmod_syscon_reboot__296_100_syscon_reboot_driver_init) ;
		*(.initcall6.init..kmod_hisi_thermal__351_665_hisi_thermal_driver_init) ;
		*(.initcall6.init..kmod_s3c2410_builtin_wdt__295_154_s3c2410_builtin_wdt_driver_init) ;
		*(.initcall6.init..kmod_dm_mod__464_3106_dm_init) ;
		*(.initcall6.init..kmod_dm_bufio__450_2163_dm_bufio_init) ;
		*(.initcall6.init..kmod_dm_crypt__569_3676_dm_crypt_init) ;
		*(.initcall6.init..kmod_dm_default_key__411_416_dm_default_key_init) ;
		*(.initcall6.init..kmod_dm_snapshot__462_2885_dm_snapshot_init) ;
		*(.initcall6.init..kmod_dm_verity__424_1422_dm_verity_init) ;
		*(.initcall6.init..kmod_dm_verity__409_193_alta_bigdata_init) ;
		*(.initcall6.init..kmod_dm_bow__457_1314_dm_bow_init) ;
		*(.initcall6.init..kmod_dm_user__432_1286_dm_user_init) ;
		*(.initcall6.init..kmod_hci_uart__709_923_hci_uart_init) ;
		*(.initcall6.init..kmod_btsdio__696_375_btsdio_driver_init) ;
		*(.initcall6.init..kmod_scmi_cpufreq__317_335_scmi_cpufreq_drv_init) ;
		*(.initcall6.init..kmod_scpi_cpufreq__317_233_scpi_cpufreq_platdrv_init) ;
		*(.initcall6.init..kmod_cpuidle_arm__304_168_arm_idle_init) ;
		*(.initcall6.init..kmod_cpuidle_psci__308_463_psci_idle_init) ;
		*(.initcall6.init..kmod_mmc_block__439_3177_mmc_blk_init) ;
		*(.initcall6.init..kmod_sdhci__562_4960_sdhci_drv_init) ;
		*(.initcall6.init..kmod_sdhci_pltfm__409_258_sdhci_pltfm_drv_init) ;
		*(.initcall6.init..kmod_ledtrig_timer__304_136_timer_led_trigger_init) ;
		*(.initcall6.init..kmod_ledtrig_transient__305_194_transient_trigger_init) ;
		*(.initcall6.init..kmod_arm_scpi__424_1056_scpi_driver_init) ;
		*(.initcall6.init..kmod_sysfb__454_127_sysfb_init) ;
		*(.initcall6.init..kmod_esrt__351_432_esrt_sysfs_init) ;
		*(.initcall6.init..kmod_efi_pstore__346_462_efivars_pstore_init) ;
		*(.initcall6.init..kmod_smccc__265_61_smccc_devices_init) ;
		*(.initcall6.init..kmod_soc_id__319_106_smccc_soc_init) ;
		*(.initcall6.init..kmod_hid__397_2640_hid_init) ;
		*(.initcall6.init..kmod_uhid__331_803_uhid_misc_init) ;
		*(.initcall6.init..kmod_hid_generic__306_82_hid_generic_init) ;
		*(.initcall6.init..kmod_hid_apple__313_668_apple_driver_init) ;
		*(.initcall6.init..kmod_hid_elecom__309_137_elecom_driver_init) ;
		*(.initcall6.init..kmod_hid_logitech__346_937_lg_driver_init) ;
		*(.initcall6.init..kmod_hid_lg_g15__361_953_lg_g15_driver_init) ;
		*(.initcall6.init..kmod_hid_logitech_dj__365_2048_logi_djreceiver_driver_init) ;
		*(.initcall6.init..kmod_hid_logitech_hidpp__378_4392_hidpp_driver_init) ;
		*(.initcall6.init..kmod_hid_magicmouse__320_952_magicmouse_driver_init) ;
		*(.initcall6.init..kmod_hid_microsoft__307_467_ms_driver_init) ;
		*(.initcall6.init..kmod_hid_multitouch__338_2283_mt_driver_init) ;
		*(.initcall6.init..kmod_hid_nintendo__311_816_nintendo_hid_driver_init) ;
		*(.initcall6.init..kmod_hid_prodikeys__363_898_pk_driver_init) ;
		*(.initcall6.init..kmod_hid_picolcd__457_657_picolcd_driver_init) ;
		*(.initcall6.init..kmod_hid_plantronics__305_232_plantronics_driver_init) ;
		*(.initcall6.init..kmod_hid_playstation__320_1598_ps_init) ;
		*(.initcall6.init..kmod_hid_roccat__311_456_roccat_init) ;
		*(.initcall6.init..kmod_hid_roccat_arvo__354_453_arvo_init) ;
		*(.initcall6.init..kmod_hid_roccat_isku__351_455_isku_init) ;
		*(.initcall6.init..kmod_hid_roccat_kone__352_910_kone_init) ;
		*(.initcall6.init..kmod_hid_roccat_koneplus__354_569_koneplus_init) ;
		*(.initcall6.init..kmod_hid_roccat_konepure__348_227_konepure_init) ;
		*(.initcall6.init..kmod_hid_roccat_kovaplus__354_658_kovaplus_init) ;
		*(.initcall6.init..kmod_hid_roccat_lua__349_211_lua_driver_init) ;
		*(.initcall6.init..kmod_hid_roccat_pyra__355_605_pyra_init) ;
		*(.initcall6.init..kmod_hid_roccat_ryos__348_236_ryos_init) ;
		*(.initcall6.init..kmod_hid_roccat_savu__348_224_savu_init) ;
		*(.initcall6.init..kmod_hid_samsung__346_570_samsung_driver_init) ;
		*(.initcall6.init..kmod_hid_sony__372_3250_sony_init) ;
		*(.initcall6.init..kmod_hid_steam__326_1157_steam_controller_driver_init) ;
		*(.initcall6.init..kmod_hid_uclogic__346_426_uclogic_driver_init) ;
		*(.initcall6.init..kmod_wacom__390_2926_wacom_driver_init) ;
		*(.initcall6.init..kmod_hid_wiimote__314_1883_wiimote_hid_driver_init) ;
		*(.initcall6.init..kmod_usbhid__397_1710_hid_init) ;
		*(.initcall6.init..kmod_vhost_vsock__690_990_vhost_vsock_init) ;
		*(.initcall6.init..kmod_vhost__481_2649_vhost_init) ;
		*(.initcall6.init..kmod_ashmem__471_997_ashmem_init) ;
		*(.initcall6.init..kmod_debug_kinfo__350_194_debug_kinfo_driver_init) ;
		*(.initcall6.init..kmod_lmkd_debug__291_150_klmkd_debug_init) ;
		*(.initcall6.init..kmod_monitor__377_243_kmonitor_init) ;
		*(.initcall6.init..kmod_freecess__660_311_kfreecess_init) ;
		*(.initcall6.init..kmod_freecess_pkg__767_295_kfreecess_pkg_init) ;
		*(.initcall6.init..kmod_sun6i_msgbox__339_322_sun6i_msgbox_driver_init) ;
		*(.initcall6.init..kmod_extcon_core__325_1441_extcon_class_init) ;
		*(.initcall6.init..kmod_binder__558_7013_binder_init) ;
		*(.initcall6.init..kmod_android_debug_symbols__450_142_debug_symbol_init) ;
		*(.initcall6.init..kmod_gnss__352_409_gnss_module_init) ;
		*(.initcall6.init..kmod_icc_core__438_1157_icc_init) ;
		*(.initcall6.init..kmod_ngksm_main__291_77_ngksm_init) ;
		*(.initcall6.init..kmod_usb_vendor_notify__344_174_usb_vendor_notify_init) ;
		*(.initcall6.init..kmod_kernelsu__676_118_kernelsu_init) ;
		*(.initcall6.init..kmod_snd_hwdep__330_544_alsa_hwdep_init) ;
		*(.initcall6.init..kmod_snd_timer__412_2347_alsa_timer_init) ;
		*(.initcall6.init..kmod_snd_hrtimer__346_168_snd_hrtimer_init) ;
		*(.initcall6.init..kmod_snd_pcm__379_1240_alsa_pcm_init) ;
		*(.initcall6.init..kmod_snd_rawmidi__403_2046_alsa_rawmidi_init) ;
		*(.initcall6.init..kmod_snd_usb_audio__417_1348_usb_audio_driver_init) ;
		*(.initcall6.init..kmod_snd_soc_core__524_3420_snd_soc_init) ;
		*(.initcall6.init..kmod_sock_diag__680_339_sock_diag_init) ;
		*(.initcall6.init..kmod_llc__482_149_llc_init) ;
		*(.initcall6.init..kmod_psnap__483_109_snap_init) ;
		*(.initcall6.init..kmod_sch_blackhole__497_41_blackhole_init) ;
		*(.initcall6.init..kmod_act_police__516_469_police_init_module) ;
		*(.initcall6.init..kmod_act_gact__509_308_gact_init_module) ;
		*(.initcall6.init..kmod_act_mirred__525_517_mirred_init_module) ;
		*(.initcall6.init..kmod_act_skbedit__721_378_skbedit_init_module) ;
		*(.initcall6.init..kmod_act_bpf__667_450_bpf_init_module) ;
		*(.initcall6.init..kmod_sch_htb__550_2192_htb_module_init) ;
		*(.initcall6.init..kmod_sch_ingress__500_315_ingress_module_init) ;
		*(.initcall6.init..kmod_sch_sfq__698_938_sfq_module_init) ;
		*(.initcall6.init..kmod_sch_tbf__514_609_tbf_module_init) ;
		*(.initcall6.init..kmod_sch_prio__501_439_prio_module_init) ;
		*(.initcall6.init..kmod_sch_multiq__501_417_multiq_module_init) ;
		*(.initcall6.init..kmod_sch_netem__693_1294_netem_module_init) ;
		*(.initcall6.init..kmod_sch_codel__675_304_codel_module_init) ;
		*(.initcall6.init..kmod_sch_fq_codel__687_726_fq_codel_module_init) ;
		*(.initcall6.init..kmod_sch_fq__780_1078_fq_module_init) ;
		*(.initcall6.init..kmod_cls_u32__541_1471_init_u32) ;
		*(.initcall6.init..kmod_cls_fw__516_457_init_fw) ;
		*(.initcall6.init..kmod_cls_basic__516_352_init_basic) ;
		*(.initcall6.init..kmod_cls_flow__774_720_cls_flow_init) ;
		*(.initcall6.init..kmod_cls_bpf__686_714_cls_bpf_init_mod) ;
		*(.initcall6.init..kmod_cls_matchall__504_437_cls_mall_init) ;
		*(.initcall6.init..kmod_em_cmp__502_92_init_em_cmp) ;
		*(.initcall6.init..kmod_em_nbyte__502_73_init_em_nbyte) ;
		*(.initcall6.init..kmod_em_u32__502_57_init_em_u32) ;
		*(.initcall6.init..kmod_em_meta__700_1008_init_em_meta) ;
		*(.initcall6.init..kmod_em_text__502_152_init_em_text) ;
		*(.initcall6.init..kmod_nfnetlink__673_730_nfnetlink_init) ;
		*(.initcall6.init..kmod_nfnetlink_queue__843_1607_nfnetlink_queue_init) ;
		*(.initcall6.init..kmod_nfnetlink_log__767_1205_nfnetlink_log_init) ;
		*(.initcall6.init..kmod_nf_conntrack__752_1260_nf_conntrack_standalone_init) ;
		*(.initcall6.init..kmod_nf_conntrack_netlink__772_3926_ctnetlink_init) ;
		*(.initcall6.init..kmod_nf_conntrack_amanda__756_239_nf_conntrack_amanda_init) ;
		*(.initcall6.init..kmod_nf_conntrack_ftp__817_613_nf_conntrack_ftp_init) ;
		*(.initcall6.init..kmod_nf_conntrack_h323__828_1837_nf_conntrack_h323_init) ;
		*(.initcall6.init..kmod_nf_conntrack_irc__752_307_nf_conntrack_irc_init) ;
		*(.initcall6.init..kmod_nf_conntrack_netbios_ns__748_69_nf_conntrack_netbios_ns_init) ;
		*(.initcall6.init..kmod_nf_conntrack_pptp__753_636_nf_conntrack_pptp_init) ;
		*(.initcall6.init..kmod_nf_conntrack_sane__746_220_nf_conntrack_sane_init) ;
		*(.initcall6.init..kmod_nf_conntrack_tftp__752_140_nf_conntrack_tftp_init) ;
		*(.initcall6.init..kmod_nf_nat__765_1186_nf_nat_init) ;
		*(.initcall6.init..kmod_nf_nat_amanda__746_91_nf_nat_amanda_init) ;
		*(.initcall6.init..kmod_nf_nat_ftp__746_150_nf_nat_ftp_init) ;
		*(.initcall6.init..kmod_nf_nat_irc__746_121_nf_nat_irc_init) ;
		*(.initcall6.init..kmod_nf_nat_tftp__746_55_nf_nat_tftp_init) ;
		*(.initcall6.init..kmod_nf_conncount__761_620_nf_conncount_modinit) ;
		*(.initcall6.init..kmod_x_tables__807_2015_xt_init) ;
		*(.initcall6.init..kmod_xt_tcpudp__771_231_tcpudp_mt_init) ;
		*(.initcall6.init..kmod_xt_mark__488_81_mark_mt_init) ;
		*(.initcall6.init..kmod_xt_connmark__769_260_connmark_mt_init) ;
		*(.initcall6.init..kmod_xt_nat__739_238_xt_nat_init) ;
		*(.initcall6.init..kmod_xt_CLASSIFY__768_69_classify_tg_init) ;
		*(.initcall6.init..kmod_xt_CONNSECMARK__748_138_connsecmark_tg_init) ;
		*(.initcall6.init..kmod_xt_CT__806_384_xt_ct_tg_init) ;
		*(.initcall6.init..kmod_xt_DSCP__686_160_dscp_tg_init) ;
		*(.initcall6.init..kmod_xt_NETMAP__803_162_netmap_tg_init) ;
		*(.initcall6.init..kmod_xt_NFLOG__485_88_nflog_tg_init) ;
		*(.initcall6.init..kmod_xt_NFQUEUE__685_157_nfqueue_tg_init) ;
		*(.initcall6.init..kmod_xt_REDIRECT__805_117_redirect_tg_init) ;
		*(.initcall6.init..kmod_xt_MASQUERADE__743_123_masquerade_tg_init) ;
		*(.initcall6.init..kmod_xt_SECMARK__485_190_secmark_tg_init) ;
		*(.initcall6.init..kmod_xt_TPROXY__765_284_tproxy_tg_init) ;
		*(.initcall6.init..kmod_xt_TCPMSS__773_344_tcpmss_tg_init) ;
		*(.initcall6.init..kmod_xt_TEE__697_224_tee_tg_init) ;
		*(.initcall6.init..kmod_xt_TRACE__484_53_trace_tg_init) ;
		*(.initcall6.init..kmod_xt_IDLETIMER__677_786_idletimer_tg_init) ;
		*(.initcall6.init..kmod_xt_bpf__522_152_bpf_mt_init) ;
		*(.initcall6.init..kmod_xt_comment__485_45_comment_mt_init) ;
		*(.initcall6.init..kmod_xt_connlimit__742_131_connlimit_mt_init) ;
		*(.initcall6.init..kmod_xt_conntrack__746_326_conntrack_mt_init) ;
		*(.initcall6.init..kmod_xt_dscp__686_109_dscp_mt_init) ;
		*(.initcall6.init..kmod_xt_ecn__767_175_ecn_mt_init) ;
		*(.initcall6.init..kmod_xt_esp__767_103_esp_mt_init) ;
		*(.initcall6.init..kmod_xt_hashlimit__787_1331_hashlimit_mt_init) ;
		*(.initcall6.init..kmod_xt_helper__749_95_helper_mt_init) ;
		*(.initcall6.init..kmod_xt_hl__684_92_hl_mt_init) ;
		*(.initcall6.init..kmod_xt_iprange__678_130_iprange_mt_init) ;
		*(.initcall6.init..kmod_xt_l2tp__768_354_l2tp_mt_init) ;
		*(.initcall6.init..kmod_xt_length__711_66_length_mt_init) ;
		*(.initcall6.init..kmod_xt_limit__488_214_limit_mt_init) ;
		*(.initcall6.init..kmod_xt_mac__767_62_mac_mt_init) ;
		*(.initcall6.init..kmod_xt_multiport__767_175_multiport_mt_init) ;
		*(.initcall6.init..kmod_xt_owner__670_152_owner_mt_init) ;
		*(.initcall6.init..kmod_xt_pkttype__684_60_pkttype_mt_init) ;
		*(.initcall6.init..kmod_xt_policy__716_186_policy_mt_init) ;
		*(.initcall6.init..kmod_xt_quota__485_91_quota_mt_init) ;
		*(.initcall6.init..kmod_xt_quota2__486_390_quota_mt2_init) ;
		*(.initcall6.init..kmod_xt_socket__763_329_socket_mt_init) ;
		*(.initcall6.init..kmod_xt_state__745_74_state_mt_init) ;
		*(.initcall6.init..kmod_xt_statistic__485_98_statistic_mt_init) ;
		*(.initcall6.init..kmod_xt_string__486_92_string_mt_init) ;
		*(.initcall6.init..kmod_xt_time__479_294_time_mt_init) ;
		*(.initcall6.init..kmod_xt_u32__479_139_u32_mt_init) ;
		*(.initcall6.init..kmod_xt_domainfilter__670_146_domainfilter_mt_init) ;
		*(.initcall6.init..kmod_gre_offload__728_294_gre_offload_init) ;
		*(.initcall6.init..kmod_sysctl_net_ipv4__763_1459_sysctl_ipv4_init) ;
		*(.initcall6.init..kmod_ipip__748_714_ipip_init) ;
		*(.initcall6.init..kmod_gre__743_216_gre_init) ;
		*(.initcall6.init..kmod_ip_gre__752_1798_ipgre_init) ;
		*(.initcall6.init..kmod_ip_vti__746_722_vti_init) ;
		*(.initcall6.init..kmod_esp4__773_1244_esp4_init) ;
		*(.initcall6.init..kmod_tunnel4__716_295_tunnel4_init) ;
		*(.initcall6.init..kmod_nf_defrag_ipv4__750_170_nf_defrag_init) ;
		*(.initcall6.init..kmod_nf_nat_h323__820_627_init) ;
		*(.initcall6.init..kmod_nf_nat_pptp__752_323_nf_nat_helper_pptp_init) ;
		*(.initcall6.init..kmod_ip_tables__713_1950_ip_tables_init) ;
		*(.initcall6.init..kmod_iptable_filter__710_116_iptable_filter_init) ;
		*(.initcall6.init..kmod_iptable_mangle__709_142_iptable_mangle_init) ;
		*(.initcall6.init..kmod_iptable_nat__750_176_iptable_nat_init) ;
		*(.initcall6.init..kmod_iptable_raw__707_116_iptable_raw_init) ;
		*(.initcall6.init..kmod_iptable_security__709_104_iptable_security_init) ;
		*(.initcall6.init..kmod_ipt_ah__483_87_ah_mt_init) ;
		*(.initcall6.init..kmod_ipt_rpfilter__709_125_rpfilter_mt_init) ;
		*(.initcall6.init..kmod_ipt_REJECT__709_110_reject_tg_init) ;
		*(.initcall6.init..kmod_arp_tables__671_1665_arp_tables_init) ;
		*(.initcall6.init..kmod_arpt_mangle__668_91_arpt_mangle_init) ;
		*(.initcall6.init..kmod_arptable_filter__483_98_arptable_filter_init) ;
		*(.initcall6.init..kmod_inet_diag__772_1480_inet_diag_init) ;
		*(.initcall6.init..kmod_tcp_diag__756_235_tcp_diag_init) ;
		*(.initcall6.init..kmod_udp_diag__700_296_udp_diag_init) ;
		*(.initcall6.init..kmod_tcp_cubic__779_526_cubictcp_register) ;
		*(.initcall6.init..kmod_xfrm_user__714_3696_xfrm_user_init) ;
		*(.initcall6.init..kmod_xfrm_interface__809_1026_xfrmi_init) ;
		*(.initcall6.init..kmod_ipv6__829_1317_inet6_init) ;
		*(.initcall6.init..kmod_ah6__742_799_ah6_init) ;
		*(.initcall6.init..kmod_esp6__806_1296_esp6_init) ;
		*(.initcall6.init..kmod_ipcomp6__736_212_ipcomp6_init) ;
		*(.initcall6.init..kmod_xfrm6_tunnel__714_398_xfrm6_tunnel_init) ;
		*(.initcall6.init..kmod_tunnel6__720_303_tunnel6_init) ;
		*(.initcall6.init..kmod_mip6__705_407_mip6_init) ;
		*(.initcall6.init..kmod_ip6_tables__772_1959_ip6_tables_init) ;
		*(.initcall6.init..kmod_ip6table_filter__766_116_ip6table_filter_init) ;
		*(.initcall6.init..kmod_ip6table_mangle__765_135_ip6table_mangle_init) ;
		*(.initcall6.init..kmod_ip6table_raw__763_114_ip6table_raw_init) ;
		*(.initcall6.init..kmod_nf_defrag_ipv6__808_170_nf_defrag_init) ;
		*(.initcall6.init..kmod_ip6t_rpfilter__735_149_rpfilter_mt_init) ;
		*(.initcall6.init..kmod_ip6t_REJECT__765_120_reject_tg6_init) ;
		*(.initcall6.init..kmod_ip6_vti__825_1329_vti6_tunnel_init) ;
		*(.initcall6.init..kmod_sit__783_2022_sit_init) ;
		*(.initcall6.init..kmod_ip6_tunnel__847_2393_ip6_tunnel_init) ;
		*(.initcall6.init..kmod_ip6_gre__786_2409_ip6gre_init) ;
		*(.initcall6.init..kmod_af_packet__798_4734_packet_init) ;
		*(.initcall6.init..kmod_af_key__715_3931_ipsec_pfkey_init) ;
		*(.initcall6.init..kmod_bridge__735_458_br_init) ;
		*(.initcall6.init..kmod_can__700_918_can_init) ;
		*(.initcall6.init..kmod_can_raw__671_974_raw_module_init) ;
		*(.initcall6.init..kmod_can_bcm__693_1773_bcm_module_init) ;
		*(.initcall6.init..kmod_can_gw__679_1321_cgw_module_init) ;
		*(.initcall6.init..kmod_rfcomm__731_2265_rfcomm_init) ;
		*(.initcall6.init..kmod_hidp__708_1472_hidp_init) ;
		*(.initcall6.init..kmod_l2tp_core__811_1719_l2tp_init) ;
		*(.initcall6.init..kmod_l2tp_ppp__727_1736_pppol2tp_init) ;
		*(.initcall6.init..kmod_8021q__491_739_vlan_proto_init) ;
		*(.initcall6.init..kmod_tipc__690_224_tipc_init) ;
		*(.initcall6.init..kmod_diag__690_112_tipc_diag_init) ;
		*(.initcall6.init..kmod_9pnet__297_182_init_p9) ;
		*(.initcall6.init..kmod_6lowpan__684_178_lowpan_module_init) ;
		*(.initcall6.init..kmod_nhc_dest__681_22_nhc_dest_init) ;
		*(.initcall6.init..kmod_nhc_fragment__681_21_nhc_fragment_init) ;
		*(.initcall6.init..kmod_nhc_hop__681_21_nhc_hop_init) ;
		*(.initcall6.init..kmod_nhc_ipv6__681_21_nhc_ipv6_init) ;
		*(.initcall6.init..kmod_nhc_mobility__681_21_nhc_mobility_init) ;
		*(.initcall6.init..kmod_nhc_routing__681_21_nhc_routing_init) ;
		*(.initcall6.init..kmod_nhc_udp__681_181_nhc_udp_init) ;
		*(.initcall6.init..kmod_ieee802154_socket__714_1139_af_ieee802154_init) ;
		*(.initcall6.init..kmod_ieee802154_6lowpan__682_280_lowpan_init_module) ;
		*(.initcall6.init..kmod_vsock__673_2419_vsock_init) ;
		*(.initcall6.init..kmod_vsock_diag__660_174_vsock_diag_init) ;
		*(.initcall6.init..kmod_vsock_loopback__670_187_vsock_loopback_init) ;
		*(.initcall6.init..kmod_ncm__804_1013_ncm_init) ;
	}
	.initcall6s.init : {
		*(.initcall6s.init..kmod_kvm__419_289_pkvm_firmware_rmem_clear) ;
	}
	.initcall7.init : {
		*(.initcall7.init..kmod_panic__373_108_kernel_panic_sysctls_init) ;
		*(.initcall7.init..kmod_panic__375_127_kernel_panic_sysfs_init) ;
		*(.initcall7.init..kmod_panic__380_629_init_oops_id) ;
		*(.initcall7.init..kmod_exit__509_107_kernel_exit_sysctls_init) ;
		*(.initcall7.init..kmod_exit__511_126_kernel_exit_sysfs_init) ;
		*(.initcall7.init..kmod_reboot__465_899_reboot_ksysfs_init) ;
		*(.initcall7.init..kmod_debug__549_344_sched_init_debug) ;
		*(.initcall7.init..kmod_qos__398_427_cpu_latency_qos_init) ;
		*(.initcall7.init..kmod_main__459_460_pm_debugfs_init) ;
		*(.initcall7.init..kmod_wakeup_reason__462_438_wakeup_reason_init) ;
		*(.initcall7.init..kmod_printk__419_3309_printk_late_init) ;
		*(.initcall7.init..kmod_srcutree__371_1468_init_srcu_module_notifier) ;
		*(.initcall7.init..kmod_swiotlb__409_755_swiotlb_create_default_debugfs) ;
		*(.initcall7.init..kmod_timekeeping_debug__450_44_tk_debug_sleep_time_init) ;
		*(.initcall7.init..kmod_kprobes__469_2845_debugfs_kprobe_init) ;
		*(.initcall7.init..kmod_taskstats__443_698_taskstats_init) ;
		*(.initcall7.init..kmod_map_iter__504_195_bpf_map_iter_init) ;
		*(.initcall7.init..kmod_task_iter__511_608_task_iter_init) ;
		*(.initcall7.init..kmod_prog_iter__504_107_bpf_prog_iter_init) ;
		*(.initcall7.init..kmod_trampoline__519_661_init_trampolines) ;
		*(.initcall7.init..kmod_system_keyring__250_167_load_system_certificate_list) ;
		*(.initcall7.init..kmod_vmscan__666_5873_init_lru_gen) ;
		*(.initcall7.init..kmod_pgsize_migration__341_111_init_pgsize_migration) ;
		*(.initcall7.init..kmod_memory__485_4430_fault_around_debugfs) ;
		*(.initcall7.init..kmod_swapfile__510_2840_max_swapfiles_check) ;
		*(.initcall7.init..kmod_core__465_694_kfence_debugfs_init) ;
		*(.initcall7.init..kmod_migrate__494_3334_migrate_on_reclaim_init) ;
		*(.initcall7.init..kmod_huge_memory__504_3178_split_huge_pages_debugfs) ;
		*(.initcall7.init..kmod_page_owner__403_693_pageowner_init) ;
		*(.initcall7.init..kmod_page_pinner__391_426_page_pinner_init) ;
		*(.initcall7.init..kmod_early_ioremap__345_98_check_early_ioremap_leak) ;
		*(.initcall7.init..kmod_cma_debug__292_200_cma_debugfs_init) ;
		*(.initcall7.init..kmod_usercopy__370_312_set_hardened_usercopy) ;
		*(.initcall7.init..kmod_fscrypto__423_440_fscrypt_init) ;
		*(.initcall7.init..kmod_init__284_61_fsverity_init) ;
		*(.initcall7.init..kmod_pstore__303_846_pstore_init) ;
		*(.initcall7.init..kmod_process_keys__419_965_init_root_keyring) ;
		*(.initcall7.init..kmod_integrity__345_280_integrity_fs_init) ;
		*(.initcall7.init..kmod_kzt__304_90_init_kzt) ;
		*(.initcall7.init..kmod_defex_lsm__380_162_defex_lsm_load) ;
		*(.initcall7.init..kmod_proca_lsm__348_374_proca_module_init) ;
		*(.initcall7.init..kmod_five__407_48_task_integrity_cache_init) ;
		*(.initcall7.init..kmod_five__458_971_init_five) ;
		*(.initcall7.init..kmod_fips140_post__297_110_fips140_post) ;
		*(.initcall7.init..kmod_crypto_algapi__527_1350_crypto_algapi_init) ;
		*(.initcall7.init..kmod_blk_timeout__411_99_blk_timeout_init) ;
		*(.initcall7.init..kmod_random32__258_634_prandom_init_late) ;
		*(.initcall7.init..kmod_error_inject__366_244_init_error_injection) ;
		*(.initcall7.init..kmod_pci__485_6667_pci_resource_alignment_sysfs_init) ;
		*(.initcall7.init..kmod_pci_sysfs__403_1424_pci_sysfs_init) ;
		*(.initcall7.init..kmod_bus__477_532_amba_deferred_retry) ;
		*(.initcall7.init..kmod_clk__525_3482_clk_debug_init) ;
		*(.initcall7.init..kmod_core__540_1163_sync_state_resume_initcall) ;
		*(.initcall7.init..kmod_dd__357_351_deferred_probe_initcall) ;
		*(.initcall7.init..kmod_domain__532_3324_genpd_debug_init) ;
		*(.initcall7.init..kmod_gpio_keys__350_1069_gpio_keys_init) ;
		*(.initcall7.init..kmod_dm_mod__410_317_dm_init_init) ;
		*(.initcall7.init..kmod_reboot__334_77_efi_shutdown_init) ;
		*(.initcall7.init..kmod_earlycon__346_50_efi_earlycon_unmap_fb) ;
		*(.initcall7.init..kmod_fdt__363_1415_of_fdt_raw_init) ;
		*(.initcall7.init..kmod_sec_debug_auto_comment_built__338_364_secdbg_comm_auto_comment_proc_init) ;
		*(.initcall7.init..kmod_sock_map__806_1619_bpf_sockmap_iter_init) ;
		*(.initcall7.init..kmod_bpf_sk_storage__691_955_bpf_sk_storage_map_iter_init) ;
		*(.initcall7.init..kmod_tcp_cong__760_256_tcp_congestion_default) ;
		*(.initcall7.init..kmod_udp_tunnel__747_959_udp_tunnel_nic_init_module) ;
		*(.initcall7.init..kmod_tcp_bpf__762_589_tcp_bpf_v4_build_proto) ;
		*(.initcall7.init..kmod_udp_bpf__758_140_udp_bpf_v4_build_proto) ;
	}
	.initcall7s.init : {
		*(.initcall7s.init..kmod_hibernate__468_1023_software_resume) ;
		*(.initcall7s.init..kmod_trace__485_9732_trace_eval_sync) ;
		*(.initcall7s.init..kmod_trace__491_10362_late_trace_init) ;
		*(.initcall7s.init..kmod_clk__477_1361_clk_disable_unused) ;
		*(.initcall7s.init..kmod_core__564_6300_regulator_init_complete) ;
		*(.initcall7s.init..kmod_domain__476_1047_genpd_power_off_unused) ;
		*(.initcall7s.init..kmod_platform__459_553_of_platform_sync_state_init) ;
		*(.initcall7s.init..kmod_sec_debug_base_built__351_408_secdbg_base_built_init) ;
		*(.initcall7s.init..kmod_sec_debug_bspinfo_built__291_43_secdbg_bspi_init) ;
		*(.initcall7s.init..kmod_sec_debug_softirq_built__547_310_secdbg_softirq_init) ;
		*(.initcall7s.init..kmod_sec_debug_cur_tasks_built__291_92_secdbg_cur_tasks_init) ;
		*(.initcall7s.init..kmod_last__265_29_alsa_sound_last_init) ;
	}
	.con_initcall.init : {
		*(.con_initcall.init..kmod_hvc_dcc__346_110_hvc_dcc_console_init) ;
		*(.con_initcall.init..kmod_hvc_console__375_246_hvc_console_init) ;
		*(.con_initcall.init..kmod_8250__375_687_univ8250_console_init) ;
		*(.con_initcall.init..kmod_samsung_tty__380_1766_s3c24xx_serial_console_init) ;
		*(.con_initcall.init..kmod_sprd_serial__382_1056_sprd_serial_console_init) ;
	}
	.initcallearly.init : {
		*(.initcallearly.init..kmod_ptrace__461_42_trace_init_flags_sys_enter) ;
		*(.initcallearly.init..kmod_ptrace__463_66_trace_init_flags_sys_exit) ;
		*(.initcallearly.init..kmod_suspend__363_163_cpu_suspend_init) ;
		*(.initcallearly.init..kmod_mmu__513_1747_prevent_bootmem_remove_init) ;
		*(.initcallearly.init..kmod_context__371_417_asids_init) ;
		*(.initcallearly.init..kmod_softirq__416_990_spawn_ksoftirqd) ;
		*(.initcallearly.init..kmod_core__833_9555_migration_init) ;
		*(.initcallearly.init..kmod_srcutree__368_1387_srcu_bootup_announce) ;
		*(.initcallearly.init..kmod_tree__704_4595_rcu_spawn_gp_kthread) ;
		*(.initcallearly.init..kmod_tree__716_107_check_cpu_stall_init) ;
		*(.initcallearly.init..kmod_tree__816_1013_rcu_sysrq_init) ;
		*(.initcallearly.init..kmod_stop_machine__355_588_cpu_stop_init) ;
		*(.initcallearly.init..kmod_kprobes__452_2536_init_kprobes) ;
		*(.initcallearly.init..kmod_trace_printk__388_422_init_trace_printk) ;
		*(.initcallearly.init..kmod_trace_events__492_3780_event_trace_enable_again) ;
		*(.initcallearly.init..kmod_jump_label__311_774_jump_label_init_module) ;
		*(.initcallearly.init..kmod_memory__461_165_init_zero_pfn) ;
		*(.initcallearly.init..kmod_dynamic_debug__716_1140_dynamic_debug_init) ;
		*(.initcallearly.init..kmod_vsprintf__687_798_initialize_ptr_random) ;
		*(.initcallearly.init..kmod_irq_gic_v3_its_platform_msi__304_163_its_pmsi_init) ;
		*(.initcallearly.init..kmod_irq_gic_v3_its_pci_msi__365_203_its_pci_msi_init) ;
		*(.initcallearly.init..kmod_uid_sys_stats__363_583_proc_uid_sys_stats_init) ;
		*(.initcallearly.init..kmod_efi__359_1005_efi_memreserve_root_init) ;
		*(.initcallearly.init..kmod_arm_runtime__363_153_arm_enable_runtime_services) ;
		*(.initcallearly.init..kmod_earlycon__344_41_efi_earlycon_remap_fb) ;
		*(.initcallearly.init..kmod_dummy_timer__295_37_dummy_timer_register) ;
		*(.initcallearly.init..kmod_idle_inject__277_370_idle_inject_init) ;
	}
	.initcallrootfs.init : {
		*(.initcallrootfs.init..kmod_initramfs__382_736_populate_rootfs) ;
	}
}
